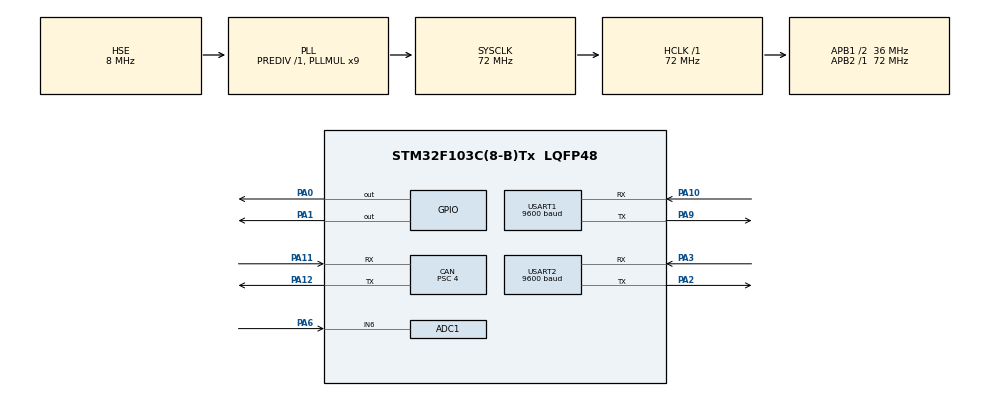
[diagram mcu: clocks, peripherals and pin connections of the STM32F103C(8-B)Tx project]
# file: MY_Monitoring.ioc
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ADC1.Channel-2\#ChannelRegularConversion=ADC_CHANNEL_6
ADC1.ContinuousConvMode=DISABLE
ADC1.EnableInjectedConversion=DISABLE
ADC1.EnableRegularConversion=ENABLE
ADC1.NbrOfConversionFlag=1
ADC1.Rank-2\#ChannelRegularConversion=1
ADC1.SamplingTime-2\#ChannelRegularConversion=ADC_SAMPLETIME_1CYCLE_5
ADC1.master=1
CAN.BS1=CAN_BS1_5TQ
CAN.BS2=CAN_BS2_3TQ
CAN.CalculateBaudRate=1000000
CAN.CalculateTimeBit=1000
CAN.CalculateTimeQuantum=111.11111111111111
CAN.Mode=CAN_MODE_NORMAL
CAN.NART=ENABLE
CAN.Prescaler=4
FREERTOS.Tasks01=defaultTask,24,128,StartDefaultTask,Default,NULL,Dynamic,NULL,NULL
Mcu.Family=STM32F1
Mcu.Name=STM32F103C(8-B)Tx
Mcu.Package=LQFP48
NVIC.PriorityGroup=NVIC_PRIORITYGROUP_4
NVIC.TIM2_IRQn=true\:5\:0\:false\:false\:true\:true\:true\:true\:true
NVIC.TIM4_IRQn=true\:15\:0\:false\:false\:true\:false\:false\:true\:true
NVIC.TimeBase=TIM4_IRQn
NVIC.TimeBaseIP=TIM4
NVIC.USART1_IRQn=true\:5\:0\:false\:false\:true\:true\:true\:true\:true
NVIC.USART2_IRQn=true\:5\:0\:false\:false\:true\:true\:true\:true\:true
NVIC.USB_LP_CAN1_RX0_IRQn=true\:5\:0\:false\:false\:true\:true\:true\:true\:true
PA0-WKUP.GPIO_Speed=GPIO_SPEED_FREQ_LOW
PA0-WKUP.PinState=GPIO_PIN_SET
PA0-WKUP.Signal=GPIO_Output
PA1.GPIO_Speed=GPIO_SPEED_FREQ_HIGH
PA1.PinState=GPIO_PIN_SET
PA1.Signal=GPIO_Output
PA10.Mode=Asynchronous
PA10.Signal=USART1_RX
PA11.Mode=CAN_Activate
PA11.Signal=CAN_RX
PA12.Mode=CAN_Activate
PA12.Signal=CAN_TX
PA13.Mode=Serial_Wire
PA13.Signal=SYS_JTMS-SWDIO
PA14.Mode=Serial_Wire
PA14.Signal=SYS_JTCK-SWCLK
PA2.Mode=Asynchronous
PA2.Signal=USART2_TX
PA3.Mode=Asynchronous
PA3.Signal=USART2_RX
PA6.Signal=ADCx_IN6
PA9.Mode=Asynchronous
PA9.Signal=USART1_TX
PD0-OSC_IN.Mode=HSE-External-Oscillator
PD0-OSC_IN.Signal=RCC_OSC_IN
PD1-OSC_OUT.Mode=HSE-External-Oscillator
PD1-OSC_OUT.Signal=RCC_OSC_OUT
ProjectManager.HeapSize=0x200
ProjectManager.StackSize=0x400
ProjectManager.TargetToolchain=MDK-ARM V5.32
RCC.ADCPresc=RCC_ADCPCLK2_DIV6
RCC.AHBFreq_Value=72000000
RCC.APB1CLKDivider=RCC_HCLK_DIV2
RCC.APB1Freq_Value=36000000
RCC.APB1TimFreq_Value=72000000
RCC.APB2Freq_Value=72000000
RCC.APB2TimFreq_Value=72000000
RCC.HCLKFreq_Value=72000000
RCC.PLLMUL=RCC_PLL_MUL9
RCC.PLLSourceVirtual=RCC_PLLSOURCE_HSE
RCC.SYSCLKFreq_VALUE=72000000
RCC.SYSCLKSource=RCC_SYSCLKSOURCE_PLLCLK
RCC.USBFreq_Value=72000000
SH.ADCx_IN6.0=ADC1_IN6,IN6
TIM2.AutoReloadPreload=TIM_AUTORELOAD_PRELOAD_ENABLE
TIM2.Period=10000
TIM2.Prescaler=72-1
USART1.BaudRate=9600
USART1.VirtualMode=VM_ASYNC
USART2.BaudRate=9600
USART2.VirtualMode=VM_ASYNC
VP_FREERTOS_VS_CMSIS_V2.Mode=CMSIS_V2
VP_SYS_VS_tim4.Mode=TIM4
VP_TIM2_VS_ClockSourceINT.Mode=Internal
board=custom

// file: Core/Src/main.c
/* USER CODE BEGIN Header */
/**
  ******************************************************************************
  * @file           : main.c
  * @brief          : Main program body
  ******************************************************************************
  * @attention
  *
  * Copyright (c) 2024 STMicroelectronics.
  * All rights reserved.
  *
  * This software is licensed under terms that can be found in the LICENSE file
  * in the root directory of this software component.
  * If no LICENSE file comes with this software, it is provided AS-IS.
  *
  ******************************************************************************
  */
/* USER CODE END Header */
#include "main.h"
#include "cmsis_os.h"
#include "adc.h"
#include "can.h"
#include "tim.h"
#include "usart.h"
#include "gpio.h"

/* USER CODE BEGIN PV */
extern void GameSoundTimer_Func(void);

/* USER CODE END PV */

void SystemClock_Config(void);
void MX_FREERTOS_Init(void);

int main(void)
{

  /* MCU Configuration--------------------------------------------------------*/

  /* Reset of all peripherals, Initializes the Flash interface and the Systick. */
  HAL_Init();

  /* Configure the system clock */
  SystemClock_Config();

  /* Initialize all configured peripherals */
  MX_GPIO_Init();
  MX_CAN_Init();
  MX_USART1_UART_Init();
  MX_ADC1_Init();
  MX_USART2_UART_Init();
  MX_TIM2_Init();

  /* Init scheduler */
  osKernelInitialize();

  /* Call init function for freertos objects (in cmsis_os2.c) */
  MX_FREERTOS_Init();

  /* Start scheduler */
  osKernelStart();

  /* We should never get here as control is now taken by the scheduler */

  /* Infinite loop */
  while (1)
  {

  }
}

void SystemClock_Config(void)
{
  RCC_OscInitTypeDef RCC_OscInitStruct = {0};
  RCC_ClkInitTypeDef RCC_ClkInitStruct = {0};
  RCC_PeriphCLKInitTypeDef PeriphClkInit = {0};

  /** Initializes the RCC Oscillators according to the specified parameters
  * in the RCC_OscInitTypeDef structure.
  */
  RCC_OscInitStruct.OscillatorType = RCC_OSCILLATORTYPE_HSE;
  RCC_OscInitStruct.HSEState = RCC_HSE_ON;
  RCC_OscInitStruct.HSEPredivValue = RCC_HSE_PREDIV_DIV1;
  RCC_OscInitStruct.HSIState = RCC_HSI_ON;
  RCC_OscInitStruct.PLL.PLLState = RCC_PLL_ON;
  RCC_OscInitStruct.PLL.PLLSource = RCC_PLLSOURCE_HSE;
  RCC_OscInitStruct.PLL.PLLMUL = RCC_PLL_MUL9;
  if (HAL_RCC_OscConfig(&RCC_OscInitStruct) != HAL_OK)
  {
    Error_Handler();
  }

  /** Initializes the CPU, AHB and APB buses clocks
  */
  RCC_ClkInitStruct.ClockType = RCC_CLOCKTYPE_HCLK|RCC_CLOCKTYPE_SYSCLK
                              |RCC_CLOCKTYPE_PCLK1|RCC_CLOCKTYPE_PCLK2;
  RCC_ClkInitStruct.SYSCLKSource = RCC_SYSCLKSOURCE_PLLCLK;
  RCC_ClkInitStruct.AHBCLKDivider = RCC_SYSCLK_DIV1;
  RCC_ClkInitStruct.APB1CLKDivider = RCC_HCLK_DIV2;
  RCC_ClkInitStruct.APB2CLKDivider = RCC_HCLK_DIV1;

  if (HAL_RCC_ClockConfig(&RCC_ClkInitStruct, FLASH_LATENCY_2) != HAL_OK)
  {
    Error_Handler();
  }
  PeriphClkInit.PeriphClockSelection = RCC_PERIPHCLK_ADC;
  PeriphClkInit.AdcClockSelection = RCC_ADCPCLK2_DIV6;
  if (HAL_RCCEx_PeriphCLKConfig(&PeriphClkInit) != HAL_OK)
  {
    Error_Handler();
  }
}

void HAL_TIM_PeriodElapsedCallback(TIM_HandleTypeDef *htim)
{
  if (htim->Instance == TIM4) {
    HAL_IncTick();
  }
  /* USER CODE BEGIN Callback 1 */
  if (htim->Instance == TIM2) {
    GameSoundTimer_Func();
  }

  /* USER CODE END Callback 1 */
}

void Error_Handler(void)
{
  __disable_irq();
  while (1)
  {
  }
}

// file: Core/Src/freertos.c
/* USER CODE BEGIN Header */
/**
  ******************************************************************************
  * File Name          : freertos.c
  * Description        : Code for freertos applications
  ******************************************************************************
  * @attention
  *
  * Copyright (c) 2024 STMicroelectronics.
  * All rights reserved.
  *
  * This software is licensed under terms that can be found in the LICENSE file
  * in the root directory of this software component.
  * If no LICENSE file comes with this software, it is provided AS-IS.
  *
  ******************************************************************************
  */
/* USER CODE END Header */

#include "FreeRTOS.h"
#include "task.h"
#include "main.h"
#include "cmsis_os.h"

/* USER CODE BEGIN Includes */
#include "Main_Task.h"
/* USER CODE END Includes */

/* Definitions for defaultTask */
osThreadId_t defaultTaskHandle;
const osThreadAttr_t defaultTask_attributes = {
  .name = "defaultTask",
  .stack_size = 128 * 4,
  .priority = (osPriority_t) osPriorityNormal,
};

void StartDefaultTask(void *argument);

void MX_FREERTOS_Init(void); /* (MISRA C 2004 rule 8.1) */

void MX_FREERTOS_Init(void) {

  /* Create the thread(s) */
  /* creation of defaultTask */
  defaultTaskHandle = osThreadNew(StartDefaultTask, NULL, &defaultTask_attributes);

  /* USER CODE BEGIN RTOS_THREADS */
  Main_Init_Start();
  /* add threads, ... */
  /* USER CODE END RTOS_THREADS */

}

void StartDefaultTask(void *argument)
{
  /* USER CODE BEGIN StartDefaultTask */
  /* Infinite loop */
  for(;;)
  {
    vTaskDelay(10);
  }
  /* USER CODE END StartDefaultTask */
}
